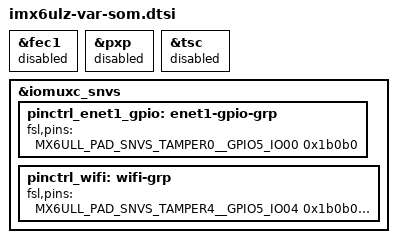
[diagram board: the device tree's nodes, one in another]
// SPDX-License-Identifier: (GPL-2.0+ OR MIT)
/*
 * Common dtsi for Variscite VAR-SOM-6ULZ
 *
 * Link: https://variscite.com/system-on-module-som/i-mx-6/i-mx-6ul/var-som-6ul/
 *
 * Copyright (C) 2026 Variscite Ltd. - https://www.variscite.com/
 *
 */

#include "imx6ul-imx6ull-var-som.dtsi"

&fec1 {
	status = "disabled";
};

&pxp {
	status = "disabled";
};

&tsc {
	status = "disabled";
};

&iomuxc_snvs {
	pinctrl_enet1_gpio: enet1-gpio-grp {
		fsl,pins = <
			MX6ULL_PAD_SNVS_TAMPER0__GPIO5_IO00	0x1b0b0
		>;
	};

	pinctrl_wifi: wifi-grp {
		fsl,pins = <
			MX6ULL_PAD_SNVS_TAMPER4__GPIO5_IO04	0x1b0b0
			MX6ULL_PAD_SNVS_TAMPER6__GPIO5_IO06	0x03029
		>;
	};
};
